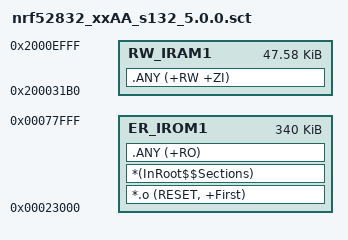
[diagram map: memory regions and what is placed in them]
; ****************************************
; *** Scatter-Loading Description File ***
; ****************************************

; Scatter file for a program IN APPLICATION SPACE, accessing the softdevice
; through SVCs.

LR_IROM1 0x00023000 0x00055000 {  ; Load region size_region
  ER_IROM1 0x00023000 0x00055000 { ; Reserve 0x8000 for the bootloader
   *.o (RESET, +First)
   *(InRoot$$Sections)
   .ANY (+RO)
  }

  RW_IRAM1 0x200031B0 0x0000BE50 { ; Reserve 0x1000 for the bootloader
   .ANY (+RW +ZI)
  }
}
